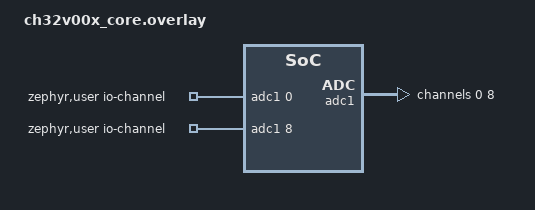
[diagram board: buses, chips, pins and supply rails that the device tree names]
/*
 * SPDX-FileCopyrightText: Copyright Michael Hope <michaelh@juju.nz>
 *
 * SPDX-License-Identifier: Apache-2.0
 */

#include <zephyr/dt-bindings/adc/adc.h>

/ {
	zephyr,user {
		io-channels = <&adc1 0>, <&adc1 8>;
	};
};

&pinctrl {
	adc1_default: adc1_default {
		group1 {
			pinmux = <ADC1_A0_PA2_0>;
		};
	};
};

&adc1 {
	#address-cells = <1>;
	#size-cells = <0>;
	status = "okay";

	pinctrl-0 = <&adc1_default>;
	pinctrl-names = "default";

	/* Channel 0 is floating */
	channel@0 {
		reg = <0>;
		zephyr,gain = "ADC_GAIN_1";
		zephyr,reference = "ADC_REF_INTERNAL";
		zephyr,acquisition-time = <ADC_ACQ_TIME_DEFAULT>;
		zephyr,resolution = <12>;
	};

	/*
	 * Channel 8 is connected to Vrefint. This is 1.2 V, or approximately
	 * 0x5D1.
	 */
	channel@8 {
		reg = <8>;
		zephyr,gain = "ADC_GAIN_1";
		zephyr,reference = "ADC_REF_INTERNAL";
		zephyr,acquisition-time = <ADC_ACQ_TIME_DEFAULT>;
		zephyr,resolution = <12>;
	};
};
